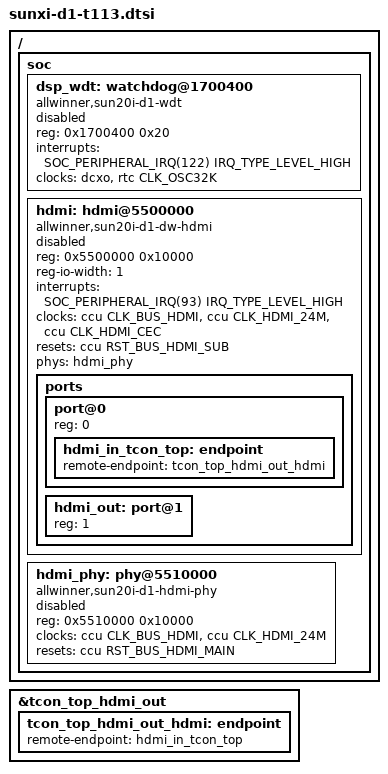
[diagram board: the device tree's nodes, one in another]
// SPDX-License-Identifier: (GPL-2.0+ or MIT)
// Copyright (C) 2021-2022 Samuel Holland <samuel@sholland.org>

/ {
	soc {
		dsp_wdt: watchdog@1700400 {
			compatible = "allwinner,sun20i-d1-wdt";
			reg = <0x1700400 0x20>;
			interrupts = <SOC_PERIPHERAL_IRQ(122) IRQ_TYPE_LEVEL_HIGH>;
			clocks = <&dcxo>, <&rtc CLK_OSC32K>;
			clock-names = "hosc", "losc";
			status = "reserved";
		};

		hdmi: hdmi@5500000 {
			compatible = "allwinner,sun20i-d1-dw-hdmi";
			reg = <0x5500000 0x10000>;
			reg-io-width = <1>;
			interrupts = <SOC_PERIPHERAL_IRQ(93) IRQ_TYPE_LEVEL_HIGH>;
			clocks = <&ccu CLK_BUS_HDMI>,
				 <&ccu CLK_HDMI_24M>,
				 <&ccu CLK_HDMI_CEC>;
			clock-names = "iahb", "isfr", "cec";
			resets = <&ccu RST_BUS_HDMI_SUB>;
			reset-names = "ctrl";
			phys = <&hdmi_phy>;
			phy-names = "phy";
			status = "disabled";

			ports {
				#address-cells = <1>;
				#size-cells = <0>;

				port@0 {
					reg = <0>;

					hdmi_in_tcon_top: endpoint {
						remote-endpoint = <&tcon_top_hdmi_out_hdmi>;
					};
				};

				hdmi_out: port@1 {
					reg = <1>;
				};
			};
		};

		hdmi_phy: phy@5510000 {
			compatible = "allwinner,sun20i-d1-hdmi-phy";
			reg = <0x5510000 0x10000>;
			clocks = <&ccu CLK_BUS_HDMI>, <&ccu CLK_HDMI_24M>;
			clock-names = "bus", "mod";
			resets = <&ccu RST_BUS_HDMI_MAIN>;
			reset-names = "phy";
			status = "disabled";
			#phy-cells = <0>;
		};
	};
};

&tcon_top_hdmi_out {
	tcon_top_hdmi_out_hdmi: endpoint {
		remote-endpoint = <&hdmi_in_tcon_top>;
	};
};
